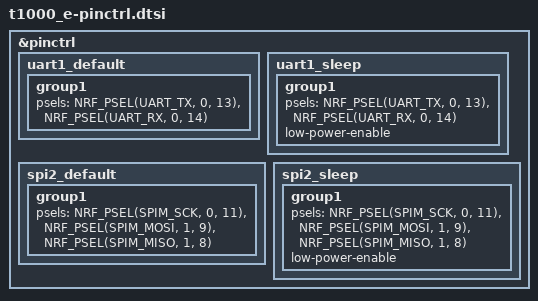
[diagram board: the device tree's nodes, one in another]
/*
 * SPDX-License-Identifier: GPL-3.0-or-later
 * SPDX-FileCopyrightText: The contributors to the LICHEN project
 *
 * Seeed SenseCAP T1000-E pin assignments.
 *
 * All assignments verified against Meshtastic firmware:
 *   variants/nrf52840/tracker-t1000-e/variant.h
 */

&pinctrl {
	/*
	 * UART1: AG3335 GNSS
	 *   TX = P0.13  RX = P0.14
	 */
	uart1_default: uart1_default {
		group1 {
			psels = <NRF_PSEL(UART_TX, 0, 13)>,
				<NRF_PSEL(UART_RX, 0, 14)>;
		};
	};
	uart1_sleep: uart1_sleep {
		group1 {
			psels = <NRF_PSEL(UART_TX, 0, 13)>,
				<NRF_PSEL(UART_RX, 0, 14)>;
			low-power-enable;
		};
	};

	/*
	 * SPI2: LR1110 radio
	 *   SCK  = P0.11  MOSI = P1.09  MISO = P1.08  CS = P0.12
	 */
	spi2_default: spi2_default {
		group1 {
			psels = <NRF_PSEL(SPIM_SCK,  0, 11)>,
				<NRF_PSEL(SPIM_MOSI, 1,  9)>,
				<NRF_PSEL(SPIM_MISO, 1,  8)>;
		};
	};
	spi2_sleep: spi2_sleep {
		group1 {
			psels = <NRF_PSEL(SPIM_SCK,  0, 11)>,
				<NRF_PSEL(SPIM_MOSI, 1,  9)>,
				<NRF_PSEL(SPIM_MISO, 1,  8)>;
			low-power-enable;
		};
	};
};
